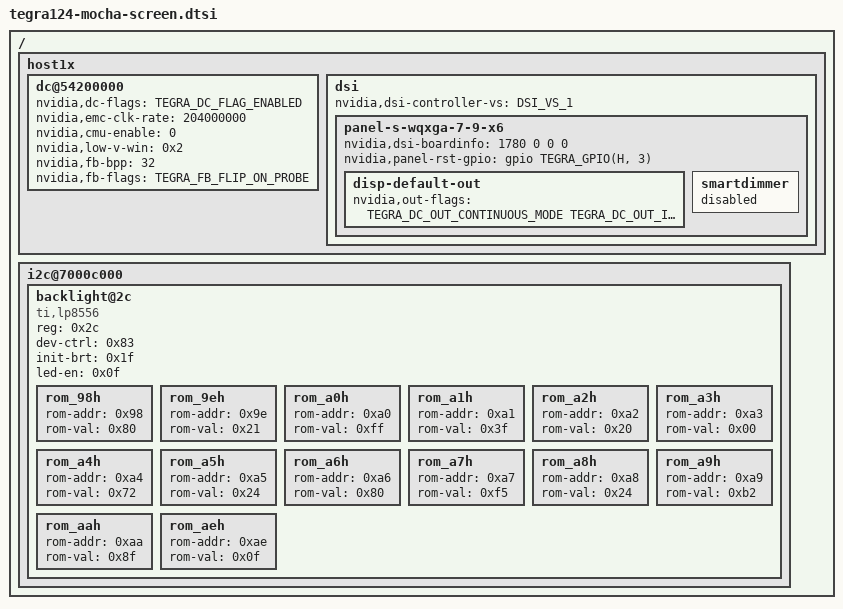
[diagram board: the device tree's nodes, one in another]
/*
 * arch/arm/boot/dts/tegra124-platforms/tegra124-mocha-screen.dtsi
 *
 * Copyright (c) 2018, Smoke team. All rights reserved.
 *
 * This program is free software; you can redistribute it and/or modify it
 * under the terms and conditions of the GNU General Public License,
 * version 2, as published by the Free Software Foundation.
 *
 * This program is distributed in the hope it will be useful, but WITHOUT
 * ANY WARRANTY; without even the implied warranty of MERCHANTABILITY or
 * FITNESS FOR A PARTICULAR PURPOSE.  See the GNU General Public License for
 * more details.
 *
 */

#include "../panel-s-wqxga-7-9-x6.dtsi"

/ {
	host1x {
		/* tegradc.0 */
		dc@54200000 {
			status = "okay";
			nvidia,dc-flags = <TEGRA_DC_FLAG_ENABLED>;
			nvidia,emc-clk-rate = <204000000>;
			nvidia,cmu-enable = <0>;
			nvidia,low-v-win = <0x2>;
			nvidia,fb-bpp = <32>; /* bits per pixel */
			nvidia,fb-flags = <TEGRA_FB_FLIP_ON_PROBE>;
		};
		dsi {
			nvidia,dsi-controller-vs = <DSI_VS_1>;
			status = "okay";
			panel-s-wqxga-7-9-x6 {
				nvidia,dsi-boardinfo = <1780 0 0 0>;
				nvidia,panel-rst-gpio = <&gpio TEGRA_GPIO(H, 3) 0>; /* PH3 */	
				disp-default-out {
					nvidia,out-flags = <TEGRA_DC_OUT_CONTINUOUS_MODE TEGRA_DC_OUT_INITIALIZED_MODE>;
				};	
				smartdimmer {
						status = "disabled";
				};
			};
		};
	};
	
	i2c@7000c000 {
		backlight@2c {
			compatible = "ti,lp8556";
			reg = <0x2c>;

			dev-ctrl = /bits/ 8 <0x83>;
			init-brt = /bits/ 8 <0x1f>;
			led-en   = /bits/ 8 <0x0f>;

			rom_98h {
				rom-addr = /bits/ 8 <0x98>;
				rom-val = /bits/ 8 <0x80>;
			};
			rom_9eh {
				rom-addr = /bits/ 8 <0x9e>;
				rom-val = /bits/ 8 <0x21>;
			};
			rom_a0h {
				rom-addr = /bits/ 8 <0xa0>;
				rom-val = /bits/ 8 <0xff>;
			};
			rom_a1h {
				rom-addr = /bits/ 8 <0xa1>;
				rom-val = /bits/ 8 <0x3f>;
			};
			rom_a2h {
				rom-addr = /bits/ 8 <0xa2>;
				rom-val = /bits/ 8 <0x20>;
			};
			rom_a3h {
				rom-addr = /bits/ 8 <0xa3>;
				rom-val = /bits/ 8 <0x00>;
			};
			rom_a4h {
				rom-addr = /bits/ 8 <0xa4>;
				rom-val = /bits/ 8 <0x72>;
			};
			rom_a5h {
				rom-addr = /bits/ 8 <0xa5>;
				rom-val = /bits/ 8 <0x24>;
			};
			rom_a6h {
				rom-addr = /bits/ 8 <0xa6>;
				rom-val = /bits/ 8 <0x80>;
			};
			rom_a7h {
				rom-addr = /bits/ 8 <0xa7>;
				rom-val = /bits/ 8 <0xf5>;
			};
			rom_a8h {
				rom-addr = /bits/ 8 <0xa8>;
				rom-val = /bits/ 8 <0x24>;
			};
			rom_a9h {
				rom-addr = /bits/ 8 <0xa9>;
				rom-val = /bits/ 8 <0xb2>;
			};
			rom_aah {
				rom-addr = /bits/ 8 <0xaa>;
				rom-val = /bits/ 8 <0x8f>;
			};
			rom_aeh {
				rom-addr = /bits/ 8 <0xae>;
				rom-val = /bits/ 8 <0x0f>;
			};
		};
	};
};
